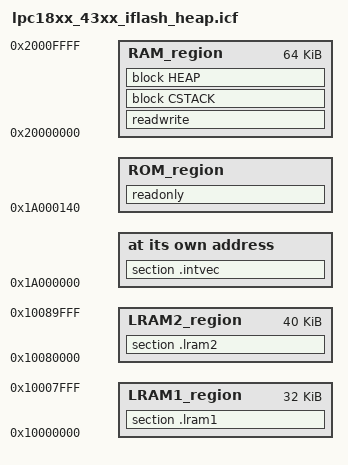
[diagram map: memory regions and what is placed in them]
/*###ICF### Section handled by ICF editor, don't touch! ****/
/*-Editor annotation file-*/
/* IcfEditorFile="$TOOLKIT_DIR$\config\ide\IcfEditor\cortex_v1_0.xml" */
/*-Specials-*/
define symbol __ICFEDIT_intvec_start__ = 0x1A000000;
/*-Memory Regions-*/
define symbol __ICFEDIT_region_ROM_start__ = 0x1A000140;
define symbol __ICFEDIT_region_ROM_end__   = 0x1B07FFFF;
define symbol __ICFEDIT_region_RAM_start__ = 0x20000000;
define symbol __ICFEDIT_region_RAM_end__   = 0x2000FFFF;
/*-Sizes-*/
define symbol __ICFEDIT_size_cstack__ = 0x800;
define symbol __ICFEDIT_size_heap__   = 0x6000;
/**** End of ICF editor section. ###ICF###*/

define symbol __region_LRAM1_start__ = 0x10000000;
define symbol __region_LRAM1_end__   = 0x10007FFF;

define symbol __region_LRAM2_start__ = 0x10080000;
define symbol __region_LRAM2_end__   = 0x10089FFF;

define symbol __ICFEDIT_region_ROM_Exclude_start__ = 0x1A080000;
define symbol __ICFEDIT_region_ROM_Exclude_end__   = 0x1AFFFFFF;

define memory mem with size = 4G;
define region ROM_region   = mem:[from __ICFEDIT_region_ROM_start__   to __ICFEDIT_region_ROM_end__] - mem:[from __ICFEDIT_region_ROM_Exclude_start__  to __ICFEDIT_region_ROM_Exclude_end__];
define region RAM_region   = mem:[from __ICFEDIT_region_RAM_start__   to __ICFEDIT_region_RAM_end__];
define region LRAM1_region = mem:[from __region_LRAM1_start__         to __region_LRAM1_end__];
define region LRAM2_region = mem:[from __region_LRAM2_start__         to __region_LRAM2_end__];

define block CSTACK    with alignment = 8, size = __ICFEDIT_size_cstack__   { };
define block HEAP      with alignment = 8, size = __ICFEDIT_size_heap__     { };

initialize by copy { readwrite };
do not initialize  { section .noinit };

place at address mem:__ICFEDIT_intvec_start__ { section .intvec };
place in ROM_region     { readonly };
place in RAM_region     { readwrite,
                          block CSTACK, block HEAP };
place in LRAM1_region   { section .lram1};
place in LRAM2_region   { section .lram2};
